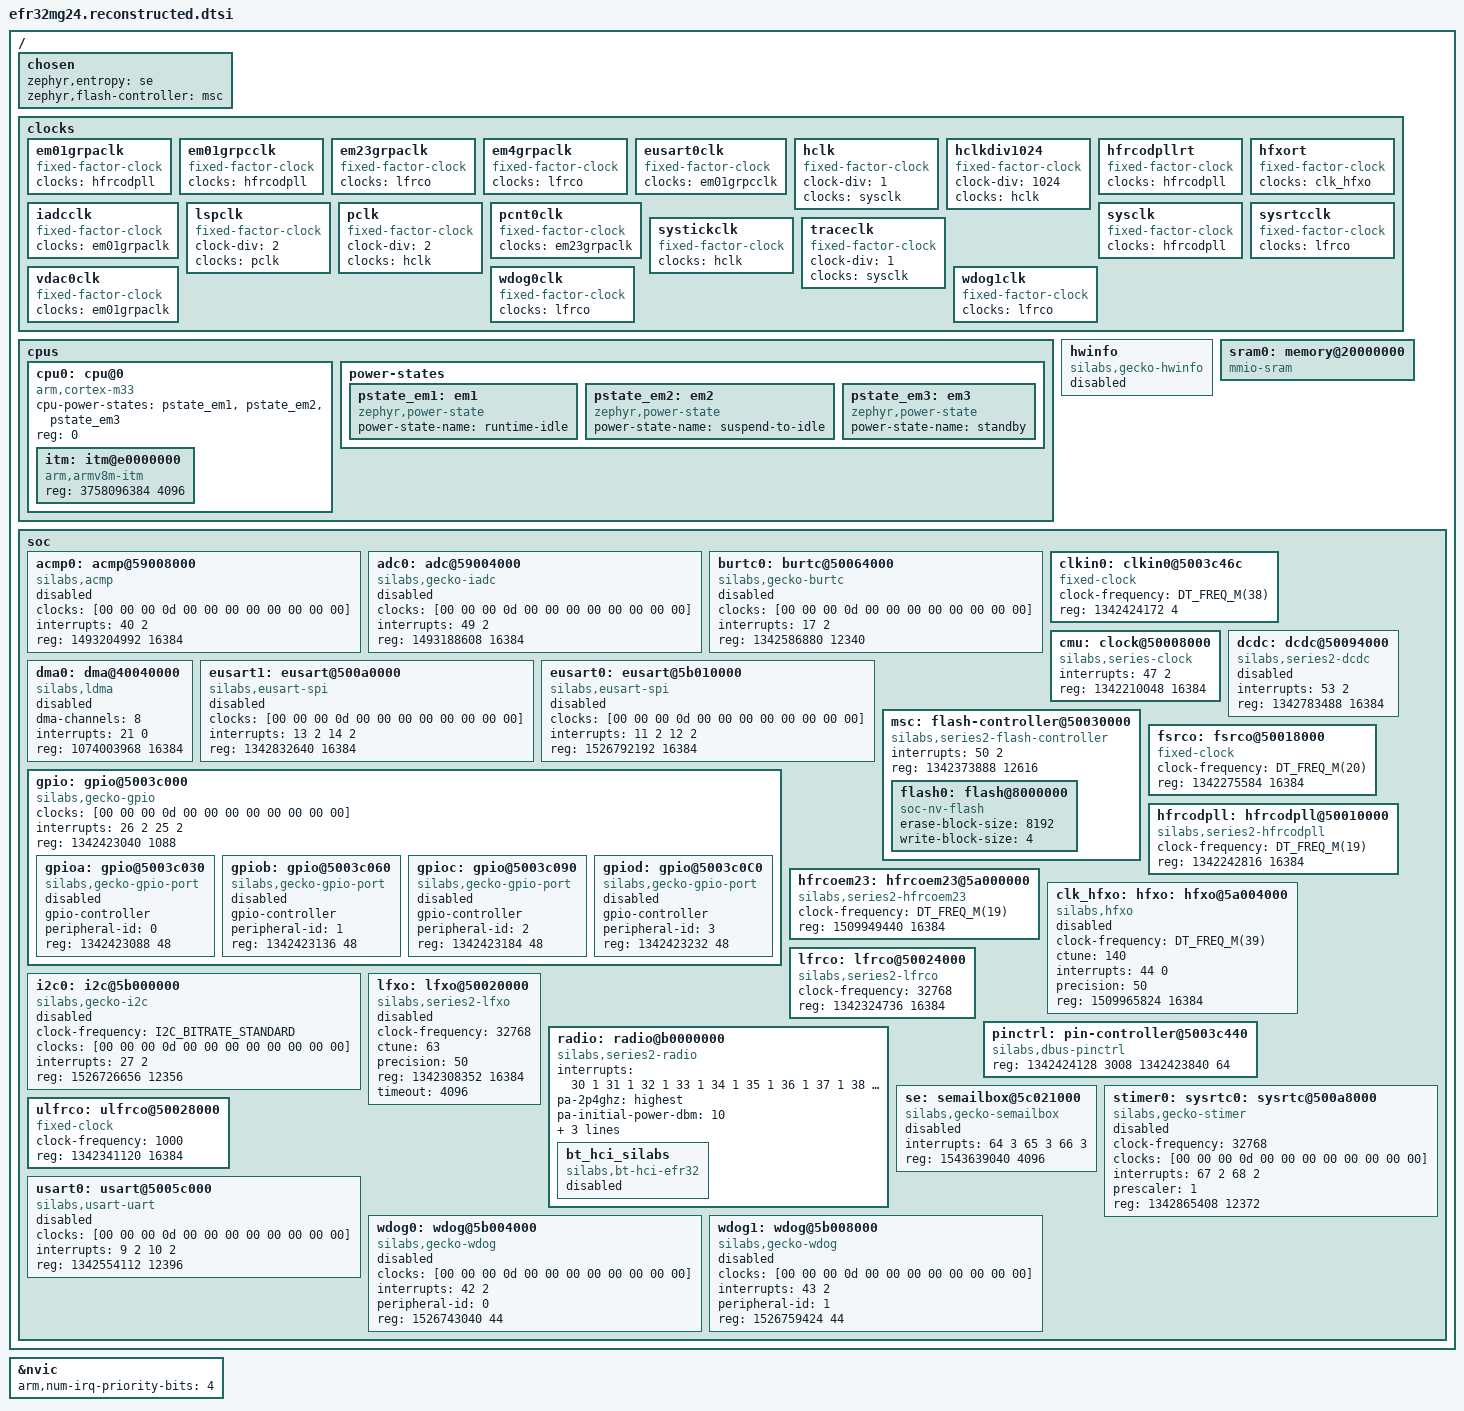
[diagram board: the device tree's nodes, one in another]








#include <arm/armv8-m.dtsi>
#include <dt-bindings/gpio/gpio.h>
#include <dt-bindings/i2c/i2c.h>
#include <dt-bindings/adc/adc.h>
#include <dt-bindings/clock/silabs/xg24-clock.h>
#include <dt-bindings/dma/silabs/xg24-dma.h>
#include <freq.h>

/ {
    chosen {
        zephyr,entropy = <&se>;

        zephyr,flash-controller = <&msc>;

    };

    clocks {
        em01grpaclk: em01grpaclk {
            #clock-cells = <0>;

            clocks = <&hfrcodpll>;

            compatible = "fixed-factor-clock";

            phandle = <6>;

        };

        em01grpcclk: em01grpcclk {
            #clock-cells = <0>;

            clocks = <&hfrcodpll>;

            compatible = "fixed-factor-clock";

            phandle = <9>;

        };

        em23grpaclk: em23grpaclk {
            #clock-cells = <0>;

            clocks = <&lfrco>;

            compatible = "fixed-factor-clock";

            phandle = <8>;

        };

        em4grpaclk: em4grpaclk {
            #clock-cells = <0>;

            clocks = <&lfrco>;

            compatible = "fixed-factor-clock";

        };

        eusart0clk: eusart0clk {
            #clock-cells = <0>;

            clocks = <&em01grpcclk>;

            compatible = "fixed-factor-clock";

        };

        hclk: hclk {
            #clock-cells = <0>;

            clock-div = <1>;

            clocks = <&sysclk>;

            compatible = "fixed-factor-clock";

            phandle = <4>;

        };

        hclkdiv1024: hclkdiv1024 {
            #clock-cells = <0>;

            clock-div = <1024>;

            clocks = <&hclk>;

            compatible = "fixed-factor-clock";

        };

        hfrcodpllrt: hfrcodpllrt {
            #clock-cells = <0>;

            clocks = <&hfrcodpll>;

            compatible = "fixed-factor-clock";

        };

        hfxort: hfxort {
            #clock-cells = <0>;

            clocks = <&clk_hfxo>;

            compatible = "fixed-factor-clock";

        };

        iadcclk: iadcclk {
            #clock-cells = <0>;

            clocks = <&em01grpaclk>;

            compatible = "fixed-factor-clock";

        };

        lspclk: lspclk {
            #clock-cells = <0>;

            clock-div = <2>;

            clocks = <&pclk>;

            compatible = "fixed-factor-clock";

        };

        pclk: pclk {
            #clock-cells = <0>;

            clock-div = <2>;

            clocks = <&hclk>;

            compatible = "fixed-factor-clock";

            phandle = <5>;

        };

        pcnt0clk: pcnt0clk {
            #clock-cells = <0>;

            clocks = <&em23grpaclk>;

            compatible = "fixed-factor-clock";

        };

        sysclk: sysclk {
            #clock-cells = <0>;

            clocks = <&hfrcodpll>;

            compatible = "fixed-factor-clock";

            phandle = <3>;

        };

        sysrtcclk: sysrtcclk {
            #clock-cells = <0>;

            clocks = <&lfrco>;

            compatible = "fixed-factor-clock";

        };

        systickclk: systickclk {
            #clock-cells = <0>;

            clocks = <&hclk>;

            compatible = "fixed-factor-clock";

        };

        traceclk: traceclk {
            #clock-cells = <0>;

            clock-div = <1>;

            clocks = <&sysclk>;

            compatible = "fixed-factor-clock";

        };

        vdac0clk: vdac0clk {
            #clock-cells = <0>;

            clocks = <&em01grpaclk>;

            compatible = "fixed-factor-clock";

        };

        wdog0clk: wdog0clk {
            #clock-cells = <0>;

            clocks = <&lfrco>;

            compatible = "fixed-factor-clock";

        };

        wdog1clk: wdog1clk {
            #clock-cells = <0>;

            clocks = <&lfrco>;

            compatible = "fixed-factor-clock";

        };

    };

    cpus {
        #address-cells = <1>;

        #size-cells = <0>;

        cpu0: cpu@0 {
            #address-cells = <1>;

            #size-cells = <1>;

            compatible = "arm,cortex-m33";

            cpu-power-states = <&pstate_em1 &pstate_em2 &pstate_em3>;

            device_type = "cpu";

            reg = <0>;

            itm: itm@e0000000 {
                compatible = "arm,armv8m-itm";

                reg = <3758096384 4096>;

            };

        };

        power-states {
            pstate_em1: em1 {
                compatible = "zephyr,power-state";

                phandle = <10>;

                power-state-name = "runtime-idle";

            };

            pstate_em2: em2 {
                compatible = "zephyr,power-state";

                phandle = <11>;

                power-state-name = "suspend-to-idle";

            };

            pstate_em3: em3 {
                compatible = "zephyr,power-state";

                phandle = <12>;

                power-state-name = "standby";

            };

        };

    };

    hwinfo: hwinfo {
        compatible = "silabs,gecko-hwinfo";

        status = "disabled";

    };

    sram0: memory@20000000 {
        compatible = "mmio-sram";

        device_type = "memory";

    };

    soc {
        acmp0: acmp@59008000 {
            clocks = [00 00 00 0d 00 00 00 00 00 00 00 00];

            compatible = "silabs,acmp";

            interrupts = <40 2>;

            reg = <1493204992 16384>;

            status = "disabled";

        };

        adc0: adc@59004000 {
            #io-channel-cells = <1>;

            clocks = [00 00 00 0d 00 00 00 00 00 00 00 00];

            compatible = "silabs,gecko-iadc";

            interrupts = <49 2>;

            reg = <1493188608 16384>;

            status = "disabled";

        };

        burtc0: burtc@50064000 {
            clocks = [00 00 00 0d 00 00 00 00 00 00 00 00];

            compatible = "silabs,gecko-burtc";

            interrupts = <17 2>;

            reg = <1342586880 12340>;

            status = "disabled";

        };

        clkin0: clkin0@5003c46c {
            #clock-cells = <0>;

            clock-frequency = <DT_FREQ_M(38)>;

            compatible = "fixed-clock";

            reg = <1342424172 4>;

        };

        cmu: clock@50008000 {
            #clock-cells = <2>;

            compatible = "silabs,series-clock";

            interrupt-names = "cmu";

            interrupts = <47 2>;

            phandle = <13>;

            reg = <1342210048 16384>;

            status = "okay";

        };

        dcdc: dcdc@50094000 {
            compatible = "silabs,series2-dcdc";

            interrupts = <53 2>;

            reg = <1342783488 16384>;

            status = "disabled";

        };

        dma0: dma@40040000 {
            #dma-cells = <1>;

            compatible = "silabs,ldma";

            dma-channels = <8>;

            interrupts = <21 0>;

            reg = <1074003968 16384>;

            status = "disabled";

        };

        eusart1: eusart@500a0000 {
            clocks = [00 00 00 0d 00 00 00 00 00 00 00 00];

            compatible = "silabs,eusart-spi";

            interrupt-names = "rx", "tx";

            interrupts = <13 2 14 2>;

            reg = <1342832640 16384>;

            status = "disabled";

        };

        eusart0: eusart@5b010000 {
            clocks = [00 00 00 0d 00 00 00 00 00 00 00 00];

            compatible = "silabs,eusart-spi";

            interrupt-names = "rx", "tx";

            interrupts = <11 2 12 2>;

            reg = <1526792192 16384>;

            status = "disabled";

        };

        msc: flash-controller@50030000 {
            #address-cells = <1>;

            #size-cells = <1>;

            compatible = "silabs,series2-flash-controller";

            interrupts = <50 2>;

            reg = <1342373888 12616>;

            flash0: flash@8000000 {
                compatible = "soc-nv-flash";

                erase-block-size = <8192>;

                write-block-size = <4>;

            };

        };

        fsrco: fsrco@50018000 {
            #clock-cells = <0>;

            clock-frequency = <DT_FREQ_M(20)>;

            compatible = "fixed-clock";

            reg = <1342275584 16384>;

        };

        gpio: gpio@5003c000 {
            #address-cells = <1>;

            #size-cells = <1>;

            clocks = [00 00 00 0d 00 00 00 00 00 00 00 00];

            compatible = "silabs,gecko-gpio";

            interrupt-names = "GPIO_EVEN", "GPIO_ODD";

            interrupts = <26 2 25 2>;

            ranges;

            reg = <1342423040 1088>;

            gpioa: gpio@5003c030 {
                #gpio-cells = <2>;

                compatible = "silabs,gecko-gpio-port";

                gpio-controller;

                peripheral-id = <0>;

                reg = <1342423088 48>;

                status = "disabled";

            };

            gpiob: gpio@5003c060 {
                #gpio-cells = <2>;

                compatible = "silabs,gecko-gpio-port";

                gpio-controller;

                peripheral-id = <1>;

                reg = <1342423136 48>;

                status = "disabled";

            };

            gpioc: gpio@5003c090 {
                #gpio-cells = <2>;

                compatible = "silabs,gecko-gpio-port";

                gpio-controller;

                peripheral-id = <2>;

                reg = <1342423184 48>;

                status = "disabled";

            };

            gpiod: gpio@5003c0C0 {
                #gpio-cells = <2>;

                compatible = "silabs,gecko-gpio-port";

                gpio-controller;

                peripheral-id = <3>;

                reg = <1342423232 48>;

                status = "disabled";

            };

        };

        hfrcodpll: hfrcodpll@50010000 {
            #clock-cells = <0>;

            clock-frequency = <DT_FREQ_M(19)>;

            compatible = "silabs,series2-hfrcodpll";

            phandle = <2>;

            reg = <1342242816 16384>;

        };

        hfrcoem23: hfrcoem23@5a000000 {
            #clock-cells = <0>;

            clock-frequency = <DT_FREQ_M(19)>;

            compatible = "silabs,series2-hfrcoem23";

            reg = <1509949440 16384>;

        };

        clk_hfxo: hfxo: hfxo@5a004000 {
            #clock-cells = <0>;

            clock-frequency = <DT_FREQ_M(39)>;

            compatible = "silabs,hfxo";

            ctune = <140>;

            interrupt-names = "hfxo";

            interrupts = <44 0>;

            phandle = <1>;

            precision = <50>;

            reg = <1509965824 16384>;

            status = "disabled";

        };

        i2c0: i2c@5b000000 {
            #address-cells = <1>;

            #size-cells = <0>;

            clock-frequency = <I2C_BITRATE_STANDARD>;

            clocks = [00 00 00 0d 00 00 00 00 00 00 00 00];

            compatible = "silabs,gecko-i2c";

            interrupts = <27 2>;

            reg = <1526726656 12356>;

            status = "disabled";

        };

        lfrco: lfrco@50024000 {
            #clock-cells = <0>;

            clock-frequency = <32768>;

            compatible = "silabs,series2-lfrco";

            phandle = <7>;

            reg = <1342324736 16384>;

        };

        lfxo: lfxo@50020000 {
            #clock-cells = <0>;

            clock-frequency = <32768>;

            compatible = "silabs,series2-lfxo";

            ctune = <63>;

            precision = <50>;

            reg = <1342308352 16384>;

            status = "disabled";

            timeout = <4096>;

        };

        pinctrl: pin-controller@5003c440 {
            compatible = "silabs,dbus-pinctrl";

            reg = <1342424128 3008 1342423840 64>;

            reg-names = "dbus", "abus";

        };

        radio: radio@b0000000 {
            compatible = "silabs,series2-radio";

            interrupt-names = "agc", "bufc", "frc_pri", "frc", "modem", "protimer", "rac_rsm", "rac_seq", "hostmailbox", "synth", "rfeca0", "rfeca1";

            interrupts = <30 1 31 1 32 1 33 1 34 1 35 1 36 1 37 1 38 1 39 1 70 1 71 1>;

            pa-2p4ghz = "highest";

            pa-initial-power-dbm = <10>;

            pa-ramp-time-us = <10>;

            pa-voltage-mv = <3300>;

            reg = <2952790016 16777216>;

            bt_hci_silabs: bt_hci_silabs {
                compatible = "silabs,bt-hci-efr32";

                status = "disabled";

            };

        };

        se: semailbox@5c021000 {
            compatible = "silabs,gecko-semailbox";

            interrupt-names = "SETAMPERHOST", "SEMBRX", "SEMBTX";

            interrupts = <64 3 65 3 66 3>;

            reg = <1543639040 4096>;

            status = "disabled";

        };

        stimer0: sysrtc0: sysrtc@500a8000 {
            clock-frequency = <32768>;

            clocks = [00 00 00 0d 00 00 00 00 00 00 00 00];

            compatible = "silabs,gecko-stimer";

            interrupt-names = "sysrtc_app", "sysrtc_seq";

            interrupts = <67 2 68 2>;

            prescaler = <1>;

            reg = <1342865408 12372>;

            status = "disabled";

        };

        ulfrco: ulfrco@50028000 {
            #clock-cells = <0>;

            clock-frequency = <1000>;

            compatible = "fixed-clock";

            reg = <1342341120 16384>;

        };

        usart0: usart@5005c000 {
            clocks = [00 00 00 0d 00 00 00 00 00 00 00 00];

            compatible = "silabs,usart-uart";

            interrupt-names = "rx", "tx";

            interrupts = <9 2 10 2>;

            reg = <1342554112 12396>;

            status = "disabled";

        };

        wdog0: wdog@5b004000 {
            clocks = [00 00 00 0d 00 00 00 00 00 00 00 00];

            compatible = "silabs,gecko-wdog";

            interrupts = <42 2>;

            peripheral-id = <0>;

            reg = <1526743040 44>;

            status = "disabled";

        };

        wdog1: wdog@5b008000 {
            clocks = [00 00 00 0d 00 00 00 00 00 00 00 00];

            compatible = "silabs,gecko-wdog";

            interrupts = <43 2>;

            peripheral-id = <1>;

            reg = <1526759424 44>;

            status = "disabled";

        };

    };

};



&nvic {
    arm,num-irq-priority-bits = <4>;

};
